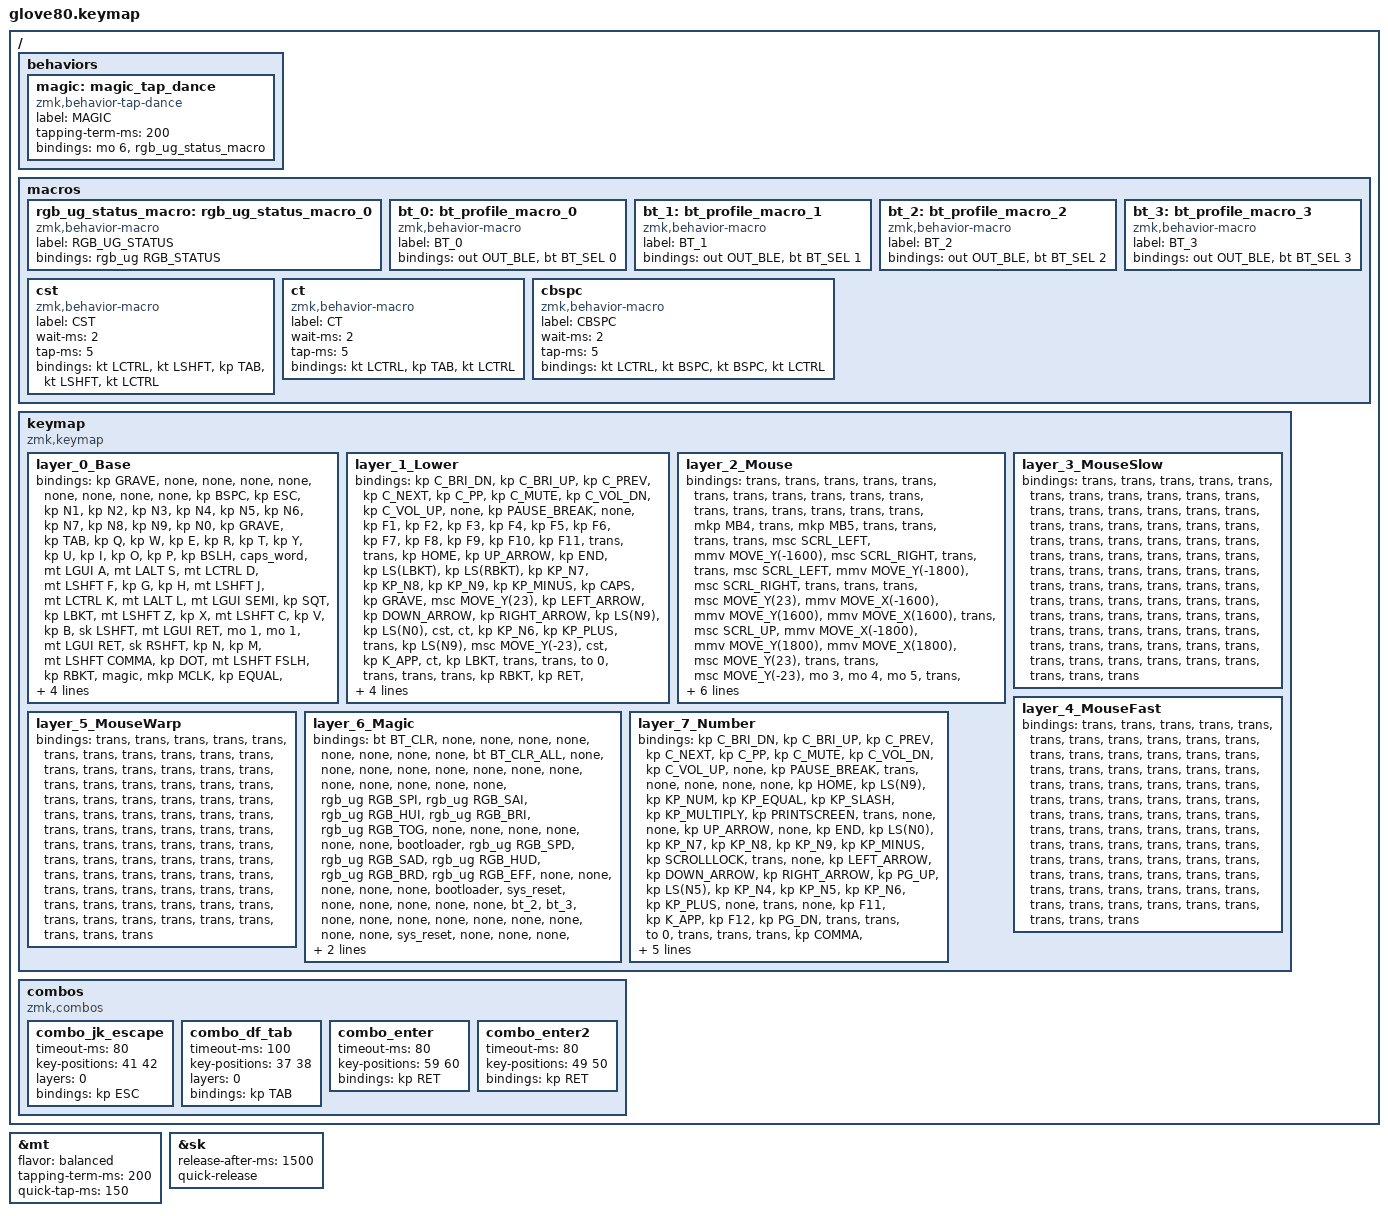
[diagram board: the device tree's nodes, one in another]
/*
 * GENERATED by tools/layout2zmk.mjs from my-layout.json — edit the JSON source, not this file.
 * Source layout: "jjamesmartiin - v48" 
 */
#include <behaviors.dtsi>
#include <dt-bindings/zmk/keys.h>
#include <dt-bindings/zmk/bt.h>
#include <dt-bindings/zmk/ext_power.h>
#include <dt-bindings/zmk/outputs.h>
#include <dt-bindings/zmk/rgb.h>
#include <dt-bindings/zmk/pointing.h>

/ {
    behaviors {
        // editor emits &magic with no cells: hold = Magic layer, double-tap = RGB status
        magic: magic_tap_dance {
            label = "MAGIC";
            compatible = "zmk,behavior-tap-dance";
            #binding-cells = <0>;
            tapping-term-ms = <200>;
            bindings = <&mo 6>, <&rgb_ug_status_macro>;
        };
    };

    macros {
        rgb_ug_status_macro: rgb_ug_status_macro_0 {
            label = "RGB_UG_STATUS";
            compatible = "zmk,behavior-macro";
            #binding-cells = <0>;
            bindings = <&rgb_ug RGB_STATUS>;
        };
        bt_0: bt_profile_macro_0 {
            label = "BT_0";
            compatible = "zmk,behavior-macro";
            #binding-cells = <0>;
            bindings = <&out OUT_BLE>, <&bt BT_SEL 0>;
        };
        bt_1: bt_profile_macro_1 {
            label = "BT_1";
            compatible = "zmk,behavior-macro";
            #binding-cells = <0>;
            bindings = <&out OUT_BLE>, <&bt BT_SEL 1>;
        };
        bt_2: bt_profile_macro_2 {
            label = "BT_2";
            compatible = "zmk,behavior-macro";
            #binding-cells = <0>;
            bindings = <&out OUT_BLE>, <&bt BT_SEL 2>;
        };
        bt_3: bt_profile_macro_3 {
            label = "BT_3";
            compatible = "zmk,behavior-macro";
            #binding-cells = <0>;
            bindings = <&out OUT_BLE>, <&bt BT_SEL 3>;
        };
        cst: cst {
            label = "CST";
            compatible = "zmk,behavior-macro";
            #binding-cells = <0>;
            wait-ms = <2>;
            tap-ms = <5>;
            bindings = <&kt LCTRL>, <&kt LSHFT>, <&kp TAB>, <&kt LSHFT>, <&kt LCTRL>;
        };
        ct: ct {
            label = "CT";
            compatible = "zmk,behavior-macro";
            #binding-cells = <0>;
            wait-ms = <2>;
            tap-ms = <5>;
            bindings = <&kt LCTRL>, <&kp TAB>, <&kt LCTRL>;
        };
        cbspc: cbspc {
            label = "CBSPC";
            compatible = "zmk,behavior-macro";
            #binding-cells = <0>;
            wait-ms = <2>;
            tap-ms = <5>;
            bindings = <&kt LCTRL>, <&kt BSPC>, <&kt BSPC>, <&kt LCTRL>;
        };
    };

    keymap {
        compatible = "zmk,keymap";

        layer_0_Base {
            bindings = <&kp GRAVE &none &none &none &none &none &none &none &none &kp BSPC &kp ESC &kp N1 &kp N2 &kp N3 &kp N4 &kp N5 &kp N6 &kp N7 &kp N8 &kp N9 &kp N0 &kp GRAVE &kp TAB &kp Q &kp W &kp E &kp R &kp T &kp Y &kp U &kp I &kp O &kp P &kp BSLH &caps_word &mt LGUI A &mt LALT S &mt LCTRL D &mt LSHFT F &kp G &kp H &mt LSHFT J &mt LCTRL K &mt LALT L &mt LGUI SEMI &kp SQT &kp LBKT &mt LSHFT Z &kp X &mt LSHFT C &kp V &kp B &sk LSHFT &mt LGUI RET &mo 1 &mo 1 &mt LGUI RET &sk RSHFT &kp N &kp M &mt LSHFT COMMA &kp DOT &mt LSHFT FSLH &kp RBKT &magic &mkp MCLK &kp EQUAL &mkp RCLK &mkp LCLK &lt 1 BSPC &mt LCTRL DEL &kp LGUI &kp RGUI &mt LCTRL RET &lt 1 SPACE &mkp LCLK &mkp RCLK &kp MINUS &mkp MCLK &magic>;
        };

        layer_1_Lower {
            bindings = <&kp C_BRI_DN &kp C_BRI_UP &kp C_PREV &kp C_NEXT &kp C_PP &kp C_MUTE &kp C_VOL_DN &kp C_VOL_UP &none &kp PAUSE_BREAK &none &kp F1 &kp F2 &kp F3 &kp F4 &kp F5 &kp F6 &kp F7 &kp F8 &kp F9 &kp F10 &kp F11 &trans &trans &kp HOME &kp UP_ARROW &kp END &kp LS(LBKT) &kp LS(RBKT) &kp KP_N7 &kp KP_N8 &kp KP_N9 &kp KP_MINUS &kp CAPS &kp GRAVE &msc MOVE_Y(23) &kp LEFT_ARROW &kp DOWN_ARROW &kp RIGHT_ARROW &kp LS(N9) &kp LS(N0) &cst &ct &kp KP_N6 &kp KP_PLUS &trans &kp LS(N9) &msc MOVE_Y(-23) &cst &kp K_APP &ct &kp LBKT &trans &trans &to 0 &trans &trans &trans &kp RBKT &kp RET &kp RET &kp KP_N3 &kp GRAVE &kp LS(N0) &magic &key_repeat &kp F12 &kp DEL &kp RET &trans &trans &trans &trans &trans &cbspc &kp RET &kp RET &kp F11 &key_repeat &trans>;
        };

        layer_2_Mouse {
            bindings = <&trans &trans &trans &trans &trans &trans &trans &trans &trans &trans &trans &trans &trans &trans &trans &trans &trans &mkp MB4 &trans &mkp MB5 &trans &trans &trans &trans &msc SCRL_LEFT &mmv MOVE_Y(-1600) &msc SCRL_RIGHT &trans &trans &msc SCRL_LEFT &mmv MOVE_Y(-1800) &msc SCRL_RIGHT &trans &trans &trans &msc MOVE_Y(23) &mmv MOVE_X(-1600) &mmv MOVE_Y(1600) &mmv MOVE_X(1600) &trans &msc SCRL_UP &mmv MOVE_X(-1800) &mmv MOVE_Y(1800) &mmv MOVE_X(1800) &msc MOVE_Y(23) &trans &trans &msc MOVE_Y(-23) &mo 3 &mo 4 &mo 5 &trans &mkp MCLK &trans &mkp MB5 &trans &trans &trans &msc SCRL_DOWN &mo 5 &mo 4 &mo 3 &msc MOVE_Y(-23) &kp CAPS &trans &trans &trans &trans &trans &mkp LCLK &mkp RCLK &mkp MB4 &trans &trans &trans &mkp LCLK &mkp RCLK &trans &mkp MCLK &trans>;
        };

        layer_3_MouseSlow {
            bindings = <&trans &trans &trans &trans &trans &trans &trans &trans &trans &trans &trans &trans &trans &trans &trans &trans &trans &trans &trans &trans &trans &trans &trans &trans &trans &trans &trans &trans &trans &trans &trans &trans &trans &trans &trans &trans &trans &trans &trans &trans &trans &trans &trans &trans &trans &trans &trans &trans &trans &trans &trans &trans &trans &trans &trans &trans &trans &trans &trans &trans &trans &trans &trans &trans &trans &trans &trans &trans &trans &trans &trans &trans &trans &trans &trans &trans &trans &trans &trans &trans>;
        };

        layer_4_MouseFast {
            bindings = <&trans &trans &trans &trans &trans &trans &trans &trans &trans &trans &trans &trans &trans &trans &trans &trans &trans &trans &trans &trans &trans &trans &trans &trans &trans &trans &trans &trans &trans &trans &trans &trans &trans &trans &trans &trans &trans &trans &trans &trans &trans &trans &trans &trans &trans &trans &trans &trans &trans &trans &trans &trans &trans &trans &trans &trans &trans &trans &trans &trans &trans &trans &trans &trans &trans &trans &trans &trans &trans &trans &trans &trans &trans &trans &trans &trans &trans &trans &trans &trans>;
        };

        layer_5_MouseWarp {
            bindings = <&trans &trans &trans &trans &trans &trans &trans &trans &trans &trans &trans &trans &trans &trans &trans &trans &trans &trans &trans &trans &trans &trans &trans &trans &trans &trans &trans &trans &trans &trans &trans &trans &trans &trans &trans &trans &trans &trans &trans &trans &trans &trans &trans &trans &trans &trans &trans &trans &trans &trans &trans &trans &trans &trans &trans &trans &trans &trans &trans &trans &trans &trans &trans &trans &trans &trans &trans &trans &trans &trans &trans &trans &trans &trans &trans &trans &trans &trans &trans &trans>;
        };

        layer_6_Magic {
            bindings = <&bt BT_CLR &none &none &none &none &none &none &none &none &bt BT_CLR_ALL &none &none &none &none &none &none &none &none &none &none &none &none &none &rgb_ug RGB_SPI &rgb_ug RGB_SAI &rgb_ug RGB_HUI &rgb_ug RGB_BRI &rgb_ug RGB_TOG &none &none &none &none &none &none &bootloader &rgb_ug RGB_SPD &rgb_ug RGB_SAD &rgb_ug RGB_HUD &rgb_ug RGB_BRD &rgb_ug RGB_EFF &none &none &none &none &none &bootloader &sys_reset &none &none &none &none &none &bt_2 &bt_3 &none &none &none &none &none &none &none &none &none &sys_reset &none &none &none &none &none &bt_0 &bt_1 &out OUT_USB &none &none &none &none &none &none &none &none>;
        };

        layer_7_Number {
            bindings = <&kp C_BRI_DN &kp C_BRI_UP &kp C_PREV &kp C_NEXT &kp C_PP &kp C_MUTE &kp C_VOL_DN &kp C_VOL_UP &none &kp PAUSE_BREAK &trans &none &none &none &none &kp HOME &kp LS(N9) &kp KP_NUM &kp KP_EQUAL &kp KP_SLASH &kp KP_MULTIPLY &kp PRINTSCREEN &trans &none &none &kp UP_ARROW &none &kp END &kp LS(N0) &kp KP_N7 &kp KP_N8 &kp KP_N9 &kp KP_MINUS &kp SCROLLLOCK &trans &none &kp LEFT_ARROW &kp DOWN_ARROW &kp RIGHT_ARROW &kp PG_UP &kp LS(N5) &kp KP_N4 &kp KP_N5 &kp KP_N6 &kp KP_PLUS &none &trans &none &kp F11 &kp K_APP &kp F12 &kp PG_DN &trans &trans &to 0 &trans &trans &trans &kp COMMA &kp KP_N1 &kp KP_N2 &kp KP_N3 &kp KP_ENTER &trans &magic &kp CAPS &kp F11 &kp INS &kp F12 &trans &trans &trans &kp KP_NUM &trans &kp KP_N0 &kp KP_N0 &kp KP_N0 &kp KP_DOT &kp KP_ENTER &trans>;
        };
    };
};

&mt {
    flavor = "balanced";
    tapping-term-ms = <200>;
    quick-tap-ms = <150>;
    /* require-prior-idle-ms = <150>; comment this out bc it was messing with vim leader key */ 
};

&sk {
    release-after-ms = <1500>;
    quick-release;
};


/ {
    combos {
        compatible = "zmk,combos";
        combo_jk_escape {
            timeout-ms = <80>;
            key-positions = <41 42>;
            layers = <0>;
            bindings = <&kp ESC>;
        };
        combo_df_tab {
            timeout-ms = <100>;
            key-positions = <37 38>;
            layers = <0>;
            bindings = <&kp TAB>;
        };
        combo_enter {
            timeout-ms = <80>;
            key-positions = <59 60>;
            bindings = <&kp RET>;
        };
        combo_enter2 {
            timeout-ms = <80>;
            key-positions = <49 50>;
            bindings = <&kp RET>;
        };
    };
};
